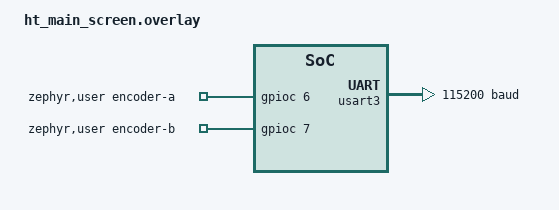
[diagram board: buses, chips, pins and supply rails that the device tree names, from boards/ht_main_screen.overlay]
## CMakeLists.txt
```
cmake_minimum_required(VERSION 3.28.0)

list(APPEND BOARD_ROOT ${CMAKE_CURRENT_SOURCE_DIR})
list(APPEND DTS_ROOT ${CMAKE_CURRENT_SOURCE_DIR})
find_package(Zephyr REQUIRED HINTS $ENV{ZEPHYR_BASE})
project(ht_firmware LANGUAGES C)

add_custom_target(code_graph_check ALL
  COMMAND ${Python3_EXECUTABLE} ${CMAKE_CURRENT_SOURCE_DIR}/tools/code_graph.py --check
  WORKING_DIRECTORY ${CMAKE_CURRENT_SOURCE_DIR}/..
  COMMENT "Checking source graph synchronization"
)
add_dependencies(app code_graph_check)

target_sources(app PRIVATE
  src/main.c
  src/platform/board_io.c
  src/platform/relay_io.c
  src/drivers/tca9539_safe.c
  src/ui/panel.c
  src/ui/dgus.c
  src/ui/view.c
  src/ui/encoder.c
  src/core/event_log.c
)
target_include_directories(app PRIVATE src)
target_compile_options(app PRIVATE -Wall -Wextra -Werror)

target_sources_ifdef(CONFIG_HT_SCREEN_BRINGUP app PRIVATE src/platform/screen_uart.c)
target_sources_ifdef(CONFIG_HT_SCREEN_BRIDGE app PRIVATE src/app/screen_bridge.c)
target_sources_ifdef(CONFIG_HT_SCREEN_PANEL app PRIVATE src/app/screen_panel.c)
target_sources_ifdef(CONFIG_HT_SCREEN_TEMPERATURE app PRIVATE
  src/core/ntc.c src/platform/temperature_io.c)
target_sources_ifdef(CONFIG_HT_DDS_BENCH app PRIVATE
  src/core/dds.c src/platform/dds_io.c src/app/dds_bench.c)
target_sources_ifdef(CONFIG_HT_OUTPUT app PRIVATE
  src/core/dds.c src/platform/dds_io.c src/core/ntc.c src/core/rms.c src/core/power.c
  src/platform/signal_io.c src/app/output.c)

target_sources_ifdef(CONFIG_HT_OUTPUT_BENCH app PRIVATE src/core/bench.c)
```

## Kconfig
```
mainmenu "HT firmware"

choice HT_SCREEN_MODE
	prompt "Screen bring-up mode"
	optional

config HT_SCREEN_BRIDGE
	bool "Transparent USART1 to USART3 bridge"
	select HT_SCREEN_BRINGUP

config HT_SCREEN_PANEL
	bool "Display and front-panel bring-up"
	select HT_SCREEN_BRINGUP

endchoice

config HT_SCREEN_BRINGUP
	bool
	select UART_INTERRUPT_DRIVEN

config HT_SCREEN_TEMPERATURE
	bool "Sample three NTC channels during panel bring-up"
	depends on HT_SCREEN_PANEL && !HT_OUTPUT
	help
	  Requires powered AVDD and the board's 22 kohm NTC pull-ups.
	  Owns ADC1 exclusively; the measurement acquisition path stays disabled.

config HT_DDS_BENCH
	bool "PA4-only DDS bench control"
	depends on HT_SCREEN_PANEL && HT_SCREEN_TEMPERATURE
	help
	  Requires the amplifier to be disconnected or unpowered. Explicit panel
	  or serial requests produce at most 100 mVpp for 60 seconds, with relays off.
	  No automatic start, output current control, or measurement acquisition.

config HT_OUTPUT
	bool "Complete VA-controlled output from the front panel"
	depends on HT_SCREEN_PANEL
	help
	  Owns ADC12, DAC1, TIM6 and relay sequencing; requires the sensor board,
	  power supply and physical safety interlocks. Never starts automatically.

config HT_OUTPUT_BENCH
	bool "Output bench operation without enclosure interlocks"
	default n
	depends on HT_OUTPUT
	help
	  Allows a bench without the coil supply monitor (BOARD_COIL). On legacy
	  wiring it also ignores the door input. On MCU-driven KSAFE wiring the
	  door is unused in both builds; the normal build still checks BOARD_COIL.
	  Keeps the independent enable, OC/OV, sensor, supply, temperature,
	  acquisition, watchdog and stop protections active.
	  Adds a panel debug page for 30-second relay checks and fixed-level
	  10-second DAC trials, owned by the same output thread.

source "Kconfig.zephyr"
```

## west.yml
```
manifest:
  version: "1.2"
  projects:
    - name: zephyr
      url: https://github.com/zephyrproject-rtos/zephyr
      revision: dccb09599635bdff17633fa7e9dab014b91dce90 # v4.4.2
      path: zephyr
      import:
        path-prefix: .tools
        name-allowlist:
          - cmsis
          - cmsis_6
          - hal_stm32
          - mcuboot
          - zcbor
  self:
    path: firmware
```

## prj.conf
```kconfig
CONFIG_GPIO=y
CONFIG_I2C=y
CONFIG_I2C_STM32_TRANSFER_TIMEOUT_MSEC=20
CONFIG_SERIAL=y
CONFIG_CONSOLE=y
CONFIG_UART_CONSOLE=y

CONFIG_LOG=y
CONFIG_LOG_MODE_DEFERRED=y
CONFIG_LOG_DEFAULT_LEVEL=3
CONFIG_LOG_BUFFER_SIZE=4096
CONFIG_LOG_PROCESS_THREAD_STACK_SIZE=1024
CONFIG_LOG_PROCESS_THREAD_CUSTOM_PRIORITY=y
CONFIG_LOG_PROCESS_THREAD_PRIORITY=6
CONFIG_LOG_BLOCK_IN_THREAD=n
CONFIG_LOG_BACKEND_UART=y
CONFIG_LOG_PRINTK=y

CONFIG_MAIN_STACK_SIZE=2048
CONFIG_MAIN_THREAD_PRIORITY=3
CONFIG_SYSTEM_WORKQUEUE_STACK_SIZE=1024
CONFIG_HEAP_MEM_POOL_SIZE=0
CONFIG_ASSERT=y
CONFIG_THREAD_STACK_INFO=y
CONFIG_INIT_STACKS=y
CONFIG_PM=n
CONFIG_PM_DEVICE=n
```

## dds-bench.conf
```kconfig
CONFIG_HT_DDS_BENCH=y
CONFIG_SHELL=y
CONFIG_SHELL_BACKEND_SERIAL=y
CONFIG_SHELL_BACKEND_SERIAL_API_INTERRUPT_DRIVEN=y
CONFIG_SHELL_BACKEND_SERIAL_RX_RING_BUFFER_SIZE=256
CONFIG_SHELL_BACKEND_SERIAL_TX_RING_BUFFER_SIZE=512
CONFIG_SHELL_STACK_SIZE=2048
CONFIG_SHELL_BACKEND_SERIAL_CHECK_DTR=n
CONFIG_SHELL_VT100_COLORS=n
CONFIG_LOG_BACKEND_UART=n
CONFIG_SHELL_LOG_BACKEND=y
CONFIG_UART_CONSOLE=n
CONFIG_CONSOLE=n
```

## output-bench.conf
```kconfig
CONFIG_HT_OUTPUT_BENCH=y
```

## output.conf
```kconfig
CONFIG_HT_OUTPUT=y
CONFIG_HT_OUTPUT_BENCH=n
CONFIG_WATCHDOG=y
CONFIG_CORTEX_M_SYSTICK_64BIT_CYCLE_COUNTER=y
CONFIG_MAIN_STACK_SIZE=3072
CONFIG_ISR_STACK_SIZE=3072
```

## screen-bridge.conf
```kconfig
CONFIG_HT_SCREEN_BRIDGE=y
CONFIG_GPIO=y
CONFIG_I2C=y
CONFIG_I2C_STM32_TRANSFER_TIMEOUT_MSEC=20
CONFIG_SERIAL=y
CONFIG_UART_INTERRUPT_DRIVEN=y
CONFIG_CONSOLE=n
CONFIG_UART_CONSOLE=n
CONFIG_LOG=n
CONFIG_PRINTK=n
CONFIG_BOOT_BANNER=n
CONFIG_MAIN_STACK_SIZE=3072
CONFIG_MAIN_THREAD_PRIORITY=3
CONFIG_HEAP_MEM_POOL_SIZE=0
CONFIG_ASSERT=y
CONFIG_THREAD_STACK_INFO=y
CONFIG_INIT_STACKS=y
CONFIG_PM=n
CONFIG_PM_DEVICE=n
```

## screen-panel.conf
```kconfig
CONFIG_HT_SCREEN_PANEL=y
CONFIG_UART_INTERRUPT_DRIVEN=y
CONFIG_MAIN_STACK_SIZE=4096
```

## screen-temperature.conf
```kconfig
CONFIG_HT_SCREEN_TEMPERATURE=y
```

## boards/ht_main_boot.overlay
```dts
/* @brief Single-slot MCUboot layout; used only by the bootloader build. */
/ {
	chosen {
		zephyr,code-partition = &slot0_partition;
	};
};

&flash0 {
	partitions {
		compatible = "fixed-partitions";
		#address-cells = <1>;
		#size-cells = <1>;

		boot_partition: partition@0 {
			label = "mcuboot";
			reg = <0x00000000 0x00010000>;
		};

		slot0_partition: partition@10000 {
			label = "image-0";
			reg = <0x00010000 0x00070000>;
		};
	};
};
```

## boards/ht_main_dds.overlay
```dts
/* The DDS bench shell exclusively owns the host UART. */
/ {
	chosen {
		zephyr,shell-uart = &usart1;
	};
};
```

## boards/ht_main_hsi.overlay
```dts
/* @brief Use HSI16 for diagnostics when the external crystal is absent. */
&clk_hse {
	status = "disabled";
};

&clk_hsi {
	status = "okay";
};

&pll {
	clocks = <&clk_hsi>;
	div-m = <4>;
};
```

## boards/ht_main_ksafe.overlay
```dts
/* Rev23 rework: separate active-high logic inputs on a dual 12 V coil driver. */
/ {
	zephyr,user {
		ksafe-gpios = <&gpioc 4 GPIO_ACTIVE_HIGH>, <&gpioc 5 GPIO_ACTIVE_HIGH>;
	};
};
```

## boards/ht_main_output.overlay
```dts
/* 整机输出的独立健康监督使能片内看门狗。 */
&iwdg { status = "okay"; };
```

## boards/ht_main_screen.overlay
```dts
/* Screen bring-up only; USART1 remains the separate host/log port. */
&usart3 {
	current-speed = <115200>;
	status = "okay";
};

/ {
	zephyr,user {
		encoder-a-gpios = <&gpioc 6 GPIO_ACTIVE_HIGH>;
		encoder-b-gpios = <&gpioc 7 GPIO_ACTIVE_HIGH>;
	};
};
```

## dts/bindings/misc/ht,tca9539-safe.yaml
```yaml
description: TCA9539 owned exclusively by the HT safe relay module
compatible: "ht,tca9539-safe"
include: i2c-device.yaml
```

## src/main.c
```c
/** @brief Initialize relay-off bring-up and dispatch the selected service. */
#include "platform/board_io.h"
#include "platform/relay_io.h"
#include "config/analog.h"
#if defined(CONFIG_HT_SCREEN_BRIDGE)
#include "app/screen_bridge.h"
#elif defined(CONFIG_HT_SCREEN_PANEL)
#include "app/screen_panel.h"
#endif

#include <zephyr/kernel.h>
#include <zephyr/logging/log.h>

LOG_MODULE_REGISTER(ht);

int main(void)
{
#if defined(CONFIG_HT_SCREEN_BRINGUP)
	int rc = board_io_init_digital();
	int relay_rc = relay_io_init();

	if (rc == 0 && relay_rc == 0) {
		LOG_INF("Screen bring-up: VREF disabled/high impedance; relay registers off");
#if defined(CONFIG_HT_SCREEN_BRIDGE)
		rc = screen_bridge_run();
#else
		rc = screen_panel_run();
#endif
	}
	int off_rc = relay_io_stop();

	LOG_ERR("Screen bring-up stopped: rc=%d relay=%d all-off=%d; reset required",
		rc, relay_rc, off_rc);
	return 0;
#else
	LOG_INF("HT bring-up: output disabled, console 115200 8N1");
	LOG_INF("Analog config: shunt=%u uOhm, divider low=%u ohm, NTC=%u ohm",
		HT_SHUNT_UOHM, HT_DIV_LOW_OHM, HT_NTC_R25_OHM);
	int rc = board_io_init();
	/* Attempt all-off even if the board/reference checks fail. */
	int relay_rc = relay_io_init();

	if (rc != 0 || relay_rc != 0) {
		LOG_ERR("Startup failed: board=%d relay=%d; reset required", rc, relay_rc);
		return 0;
	}
	LOG_INF("Clock configuration checked: 170 MHz; VREFBUF ready flag set");
	LOG_INF("Relay latch/config verified off; physical contacts unverified");
	LOG_INF("Input bits: OC OV SENSOR COIL AC DC BAT CHARGE (bit 0..7)");

	uint32_t prev = UINT32_MAX;
	uint8_t prev_panel = 0;
	bool first = true;

	for (;;) {
		uint32_t state;
		uint8_t panel;

		rc = relay_io_check();
		if (rc == 0) {
			rc = relay_io_read_panel(&panel);
		}
		if (rc == 0) {
			rc = board_io_read(&state);
		}
		if (rc != 0) {
			int off_rc = relay_io_stop();

			LOG_ERR("Check failed: %d, all-off attempt: %d; reset required", rc, off_rc);
			return 0;
		}
		if (first || state != prev || panel != prev_panel) {
			LOG_INF("Inputs=0x%02x panel_raw=0x%02x; output disabled", state, panel);
			prev = state;
			prev_panel = panel;
			first = false;
		}
		k_msleep(200);
	}
#endif
}
```
